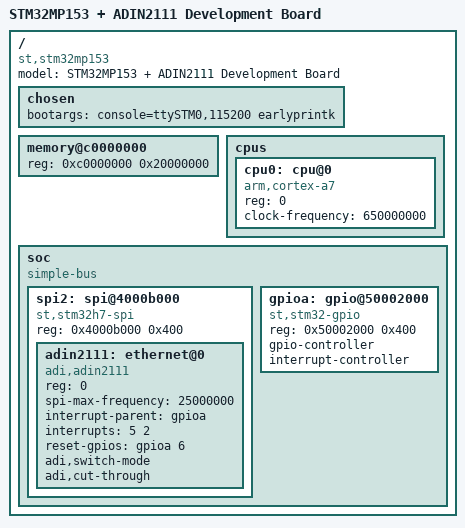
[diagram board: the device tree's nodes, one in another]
/dts-v1/;

/ {
    model = "STM32MP153 + ADIN2111 Development Board";
    compatible = "st,stm32mp153";
    
    #address-cells = <1>;
    #size-cells = <1>;
    
    chosen {
        bootargs = "console=ttySTM0,115200 earlyprintk";
    };
    
    memory@c0000000 {
        device_type = "memory";
        reg = <0xc0000000 0x20000000>; /* 512MB DDR */
    };
    
    cpus {
        #address-cells = <1>;
        #size-cells = <0>;
        
        cpu0: cpu@0 {
            device_type = "cpu";
            compatible = "arm,cortex-a7";
            reg = <0>;
            clock-frequency = <650000000>; /* 650 MHz */
        };
    };
    
    soc {
        compatible = "simple-bus";
        #address-cells = <1>;
        #size-cells = <1>;
        ranges;
        
        spi2: spi@4000b000 {
            compatible = "st,stm32h7-spi";
            reg = <0x4000b000 0x400>;
            #address-cells = <1>;
            #size-cells = <0>;
            
            adin2111: ethernet@0 {
                compatible = "adi,adin2111";
                reg = <0>;
                spi-max-frequency = <25000000>;
                
                /* STM32MP153 GPIO configuration */
                interrupt-parent = <&gpioa>;
                interrupts = <5 2>; /* GPIOA.5, falling edge */
                reset-gpios = <&gpioa 6 0>; /* GPIOA.6 */
                
                /* Switch configuration */
                adi,switch-mode;
                adi,cut-through;
            };
        };
        
        gpioa: gpio@50002000 {
            compatible = "st,stm32-gpio";
            reg = <0x50002000 0x400>;
            gpio-controller;
            #gpio-cells = <2>;
            interrupt-controller;
            #interrupt-cells = <2>;
        };
    };
};
